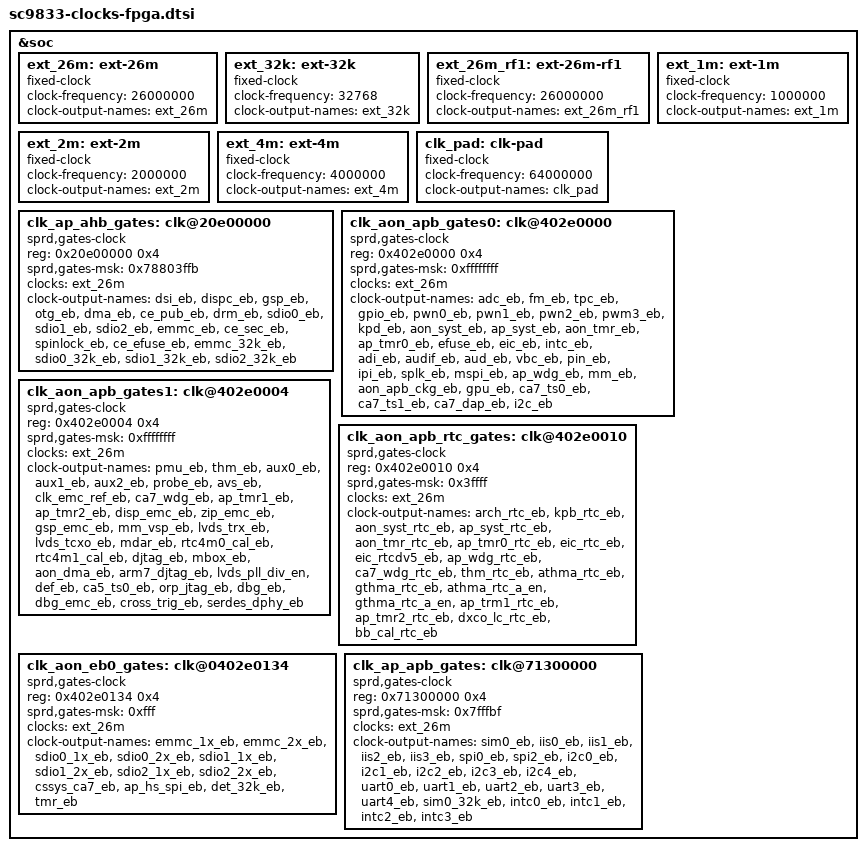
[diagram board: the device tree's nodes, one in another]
/*
 * Spreadtrum Sharkl2 Series SoC Clock DTS file
 *
 * Copyright (C) 2016, Spreadtrum Communications Inc.
 *
 * This file is licensed under a dual GPLv2 or X11 license.
 */
&soc {
	ext_26m: ext-26m {
		compatible = "fixed-clock";
		#clock-cells = <0>;
		clock-frequency = <26000000>;
		clock-output-names = "ext_26m";
	};

	ext_32k: ext-32k {
		compatible = "fixed-clock";
		#clock-cells = <0>;
		clock-frequency = <32768>;
		clock-output-names = "ext_32k";
	};

	ext_26m_rf1: ext-26m-rf1 {
		compatible = "fixed-clock";
		#clock-cells = <0>;
		clock-frequency = <26000000>;
		clock-output-names = "ext_26m_rf1";
	};

	ext_1m: ext-1m {
		compatible = "fixed-clock";
		#clock-cells = <0>;
		clock-frequency = <1000000>;
		clock-output-names = "ext_1m";
	};

	ext_2m: ext-2m {
		compatible = "fixed-clock";
		#clock-cells = <0>;
		clock-frequency = <2000000>;
		clock-output-names = "ext_2m";
	};

	ext_4m: ext-4m {
		compatible = "fixed-clock";
		#clock-cells = <0>;
		clock-frequency = <4000000>;
		clock-output-names = "ext_4m";
	};

	clk_pad: clk-pad {
		compatible = "fixed-clock";
		#clock-cells = <0>;
		clock-frequency = <64000000>;
		clock-output-names = "clk_pad";
	};

	/* Aon Ahb Gates */
	clk_ap_ahb_gates: clk@20e00000 {
		compatible = "sprd,gates-clock";
		#clock-cells = <1>;
		reg = <0x20e00000 0x4>;
		sprd,gates-msk = <0x78803ffb>;
		/* need to change to clk_ap_ahb later */
		clocks = <&ext_26m>;
		clock-output-names = "dsi_eb", "dispc_eb", "gsp_eb",
				     "otg_eb", "dma_eb", "ce_pub_eb",
				     "drm_eb", "sdio0_eb", "sdio1_eb",
				     "sdio2_eb", "emmc_eb", "ce_sec_eb",
				     "spinlock_eb", "ce_efuse_eb",
				     "emmc_32k_eb", "sdio0_32k_eb",
				     "sdio1_32k_eb", "sdio2_32k_eb";
	};

	/* Aon Apb Gates */
	clk_aon_apb_gates0: clk@402e0000 {
		compatible = "sprd,gates-clock";
		#clock-cells = <1>;
		reg = <0x402e0000 0x4>;
		sprd,gates-msk = <0xffffffff>;
		/* need to change to clk_aon_apb later */
		clocks = <&ext_26m>;
		clock-output-names = "adc_eb", "fm_eb", "tpc_eb",
				     "gpio_eb", "pwn0_eb", "pwn1_eb",
				     "pwn2_eb", "pwm3_eb", "kpd_eb",
				     "aon_syst_eb", "ap_syst_eb", "aon_tmr_eb",
				     "ap_tmr0_eb", "efuse_eb", "eic_eb",
				     "intc_eb", "adi_eb", "audif_eb",
				     "aud_eb", "vbc_eb", "pin_eb",
				     "ipi_eb", "splk_eb", "mspi_eb",
				     "ap_wdg_eb", "mm_eb", "aon_apb_ckg_eb",
				     "gpu_eb", "ca7_ts0_eb", "ca7_ts1_eb",
				     "ca7_dap_eb", "i2c_eb";
	};

	clk_aon_apb_gates1: clk@402e0004 {
		compatible = "sprd,gates-clock";
		#clock-cells = <1>;
		reg = <0x402e0004 0x4>;
		sprd,gates-msk = <0xffffffff>;
		/* need to change to clk_aon_apb later */
		clocks = <&ext_26m>;
		clock-output-names = "pmu_eb", "thm_eb", "aux0_eb",
				     "aux1_eb", "aux2_eb", "probe_eb",
				     "avs_eb", "clk_emc_ref_eb", "ca7_wdg_eb",
				     "ap_tmr1_eb", "ap_tmr2_eb", "disp_emc_eb",
				     "zip_emc_eb", "gsp_emc_eb", "mm_vsp_eb",
				     "lvds_trx_eb", "lvds_tcxo_eb", "mdar_eb",
				     "rtc4m0_cal_eb", "rtc4m1_cal_eb",
				     "djtag_eb", "mbox_eb", "aon_dma_eb",
				     "arm7_djtag_eb", "lvds_pll_div_en",
				     "def_eb", "ca5_ts0_eb", "orp_jtag_eb",
				     "dbg_eb", "dbg_emc_eb", "cross_trig_eb",
				     "serdes_dphy_eb";
	};

	clk_aon_apb_rtc_gates: clk@402e0010 {
		compatible = "sprd,gates-clock";
		#clock-cells = <1>;
		reg = <0x402e0010 0x4>;
		sprd,gates-msk = <0x3ffff>;
		/* need to change to clk_aon_apb later */
		clocks = <&ext_26m>;
		clock-output-names = "arch_rtc_eb", "kpb_rtc_eb",
				     "aon_syst_rtc_eb", "ap_syst_rtc_eb",
				     "aon_tmr_rtc_eb", "ap_tmr0_rtc_eb",
				     "eic_rtc_eb", "eic_rtcdv5_eb",
				     "ap_wdg_rtc_eb", "ca7_wdg_rtc_eb",
				     "thm_rtc_eb", "athma_rtc_eb",
				     "gthma_rtc_eb", "athma_rtc_a_en",
				     "gthma_rtc_a_en", "ap_trm1_rtc_eb",
				     "ap_tmr2_rtc_eb", "dxco_lc_rtc_eb",
				     "bb_cal_rtc_eb";
	};

	clk_aon_eb0_gates: clk@0402e0134 {
		compatible = "sprd,gates-clock";
		#clock-cells = <1>;
		reg = <0x402e0134 0x4>;
		sprd,gates-msk = <0xfff>;
		/* need to change to clk_aon_apb later */
		clocks = <&ext_26m>;
		clock-output-names = "emmc_1x_eb", "emmc_2x_eb",
				     "sdio0_1x_eb", "sdio0_2x_eb",
				     "sdio1_1x_eb", "sdio1_2x_eb",
				     "sdio2_1x_eb", "sdio2_2x_eb",
				     "cssys_ca7_eb", "ap_hs_spi_eb",
				     "det_32k_eb", "tmr_eb";
	};

	clk_ap_apb_gates: clk@71300000 {
		compatible = "sprd,gates-clock";
		#clock-cells = <1>;
		reg = <0x71300000 0x4>;
		sprd,gates-msk = <0x7fffbf>;
		/* need to change to clk_ap_apb later */
		clocks = <&ext_26m>;
		clock-output-names = "sim0_eb", "iis0_eb", "iis1_eb",
				     "iis2_eb", "iis3_eb", "spi0_eb",
				     "spi2_eb", "i2c0_eb", "i2c1_eb",
				     "i2c2_eb", "i2c3_eb", "i2c4_eb",
				     "uart0_eb", "uart1_eb", "uart2_eb",
				     "uart3_eb", "uart4_eb", "sim0_32k_eb",
				     "intc0_eb", "intc1_eb", "intc2_eb",
				     "intc3_eb";
	};
};
